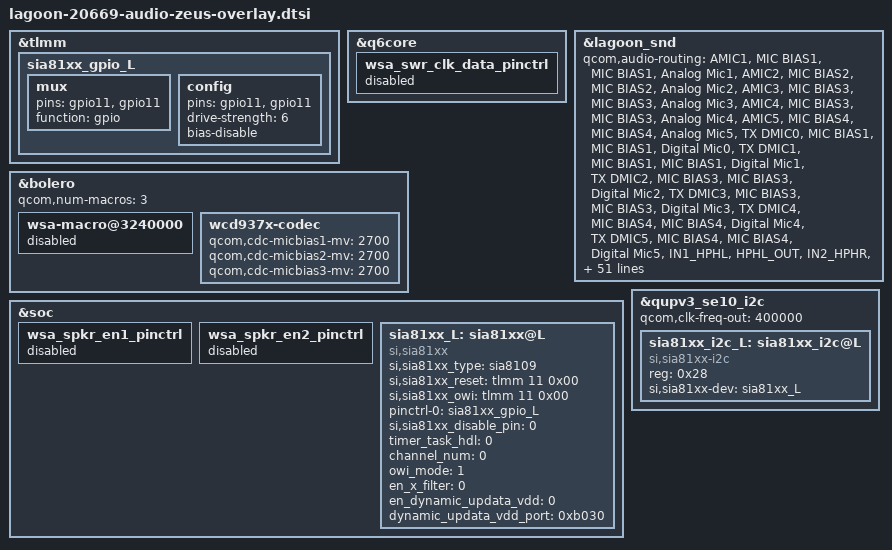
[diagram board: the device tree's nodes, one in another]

&tlmm {
	/* #ifdef OPLUS_ARCH_EXTENDS */
	sia81xx_gpio_L: sia81xx_gpio_L {
		mux {
			pins = "gpio11", "gpio11";
			function = "gpio";
		};

		config {
			pins = "gpio11", "gpio11";
			drive-strength = <6>;
			bias-disable;
		};
	};
	//#endif /* OPLUS_ARCH_EXTENDS */
};

&q6core {
        wsa_swr_clk_data_pinctrl {
                status = "disabled";
        };
};

&lagoon_snd {
	qcom,audio-routing =
		"AMIC1", "MIC BIAS1",
		"MIC BIAS1", "Analog Mic1",
		"AMIC2", "MIC BIAS2",
		"MIC BIAS2", "Analog Mic2",
		"AMIC3", "MIC BIAS3",
		"MIC BIAS3", "Analog Mic3",
		"AMIC4", "MIC BIAS3",
		"MIC BIAS3", "Analog Mic4",
		"AMIC5", "MIC BIAS4",
		"MIC BIAS4", "Analog Mic5",
		"TX DMIC0", "MIC BIAS1",
		"MIC BIAS1", "Digital Mic0",
		"TX DMIC1", "MIC BIAS1",
		"MIC BIAS1", "Digital Mic1",
		"TX DMIC2", "MIC BIAS3",
		"MIC BIAS3", "Digital Mic2",
		"TX DMIC3", "MIC BIAS3",
		"MIC BIAS3", "Digital Mic3",
		"TX DMIC4", "MIC BIAS4",
		"MIC BIAS4", "Digital Mic4",
		"TX DMIC5", "MIC BIAS4",
		"MIC BIAS4", "Digital Mic5",
		"IN1_HPHL", "HPHL_OUT",
		"IN2_HPHR", "HPHR_OUT",
		"IN3_AUX", "AUX_OUT",
		"TX SWR_ADC0", "ADC1_OUTPUT",
		//#ifdef OPLUS_ARCH_EXTENDS
		"TX SWR_ADC2", "ADC2_OUTPUT",
		//#else
		//"TX SWR_ADC1", "ADC2_OUTPUT",
		//"TX SWR_ADC2", "ADC3_OUTPUT",
		//#endif /* OPLUS_ARCH_EXTENDS */
		"TX SWR_ADC3", "ADC4_OUTPUT",
		"TX SWR_DMIC0", "DMIC1_OUTPUT",
		"TX SWR_DMIC1", "DMIC2_OUTPUT",
		"TX SWR_DMIC2", "DMIC3_OUTPUT",
		"TX SWR_DMIC3", "DMIC4_OUTPUT",
		"TX SWR_DMIC4", "DMIC5_OUTPUT",
		"TX SWR_DMIC5", "DMIC6_OUTPUT",
		"TX SWR_DMIC6", "DMIC7_OUTPUT",
		"TX SWR_DMIC7", "DMIC8_OUTPUT",
		"WSA SRC0_INP", "SRC0",
		"WSA_TX DEC0_INP", "TX DEC0 MUX",
		"WSA_TX DEC1_INP", "TX DEC1 MUX",
		"RX_TX DEC0_INP", "TX DEC0 MUX",
		"RX_TX DEC1_INP", "TX DEC1 MUX",
		"RX_TX DEC2_INP", "TX DEC2 MUX",
		"RX_TX DEC3_INP", "TX DEC3 MUX",
		"SpkrLeft IN", "WSA_SPK1 OUT",
		"SpkrRight IN", "WSA_SPK2 OUT",
		"VA_AIF1 CAP", "VA_SWR_CLK",
		"VA_AIF2 CAP", "VA_SWR_CLK",
		"VA_AIF3 CAP", "VA_SWR_CLK",
		"VA MIC BIAS1", "Digital Mic0",
		"VA MIC BIAS1", "Digital Mic1",
		"VA MIC BIAS3", "Digital Mic2",
		"VA MIC BIAS3", "Digital Mic3",
		"VA MIC BIAS4", "Digital Mic4",
		"VA MIC BIAS4", "Digital Mic5",
		"VA DMIC0", "VA MIC BIAS1",
		"VA DMIC1", "VA MIC BIAS1",
		"VA DMIC2", "VA MIC BIAS3",
		"VA DMIC3", "VA MIC BIAS3",
		"VA DMIC4", "VA MIC BIAS4",
		"VA DMIC5", "VA MIC BIAS4",
		"VA SWR_ADC0", "VA_SWR_CLK",
		"VA SWR_ADC1", "VA_SWR_CLK",
		"VA SWR_ADC2", "VA_SWR_CLK",
		"VA SWR_ADC3", "VA_SWR_CLK",
		"VA SWR_MIC0", "VA_SWR_CLK",
		"VA SWR_MIC1", "VA_SWR_CLK",
		"VA SWR_MIC2", "VA_SWR_CLK",
		"VA SWR_MIC3", "VA_SWR_CLK",
		"VA SWR_MIC4", "VA_SWR_CLK",
		"VA SWR_MIC5", "VA_SWR_CLK",
		"VA SWR_MIC6", "VA_SWR_CLK",
		"VA SWR_MIC7", "VA_SWR_CLK",
		"VA SWR_ADC0", "ADC1_OUTPUT",
		//#ifdef OPLUS_ARCH_EXTENDS
		"VA SWR_ADC2", "ADC2_OUTPUT",
		//#else /* OPLUS_ARCH_EXTENDS */
		//"VA SWR_ADC1", "ADC2_OUTPUT",
		//"VA SWR_ADC2", "ADC3_OUTPUT",
		//#endif /* OPLUS_ARCH_EXTENDS */
		"VA SWR_ADC3", "ADC4_OUTPUT",
		"VA SWR_MIC0", "DMIC1_OUTPUT",
		"VA SWR_MIC1", "DMIC2_OUTPUT",
		"VA SWR_MIC2", "DMIC3_OUTPUT",
		"VA SWR_MIC3", "DMIC4_OUTPUT",
		"VA SWR_MIC4", "DMIC5_OUTPUT",
		"VA SWR_MIC5", "DMIC6_OUTPUT",
		"VA SWR_MIC6", "DMIC7_OUTPUT",
		"VA SWR_MIC7", "DMIC8_OUTPUT";

        qcom,wsa-max-devs = <0>;
        qcom,codec-max-aux-devs = <1>;
	
        qcom,msm-mbhc-hs-mic-max-threshold-mv = <2600>;
        qcom,msm-mbhc-hs-mic-min-threshold-mv = <75>;

        oplus,mbhc-check-cross-conn = <0>;

        qcom,codec-aux-devs = <&wcd937x_codec>;
	//#ifdef OPLUS_ARCH_EXTENDS
        si,sia81xx-max-num = <1>;
        si,sia81xx-aux-devs = <&sia81xx_L>;
        si,sia81xx-aux-devs-prefix = "SpkrMonoL";
	//#endif /* OPLUS_ARCH_EXTENDS */

	//#ifdef OPLUS_ARCH_EXTENDS
	/* Huilong.Wen@LQ MULTIMEDIA.AUDIODRIVER.HeadsetDet, 2021/2/4, workaround to fix headset recording pop noise*/
	oplus,mbhc-headset-bias-alwayon = <1>;
	//#endif /* OPLUS_ARCH_EXTENDS */
 	oplus,speaker-vendor = "sia81xx";
};

&bolero {
        qcom,num-macros = <3>;

        wsa-macro@3240000 {
                status = "disabled";
        };

        wcd937x-codec {
                qcom,cdc-micbias1-mv = <2700>;
                qcom,cdc-micbias2-mv = <2700>;
                qcom,cdc-micbias3-mv = <2700>;
        };
};

&soc {

        wsa_spkr_en1_pinctrl {
                status = "disabled";
        };
        wsa_spkr_en2_pinctrl {
                status = "disabled";
        };

	//#ifdef OPLUS_ARCH_EXTENDS
	sia81xx_L: sia81xx@L {
			compatible = "si,sia81xx";
			si,sia81xx_type = "sia8109";
			si,sia81xx_reset = <&tlmm 11 0x00>;
			si,sia81xx_owi = <&tlmm 11 0x00>;
			pinctrl-names = "sia81xx_gpio";
			pinctrl-0 = <&sia81xx_gpio_L>;

			si,sia81xx_disable_pin = <0>;

			/* the same value share a same task
			 * valid value range : 0 ~ 7 */
			timer_task_hdl = <0>;

			channel_num = <0>;
			owi_mode = <1>;
			en_x_filter = <0>;
			en_dynamic_updata_vdd = <0>;
			dynamic_updata_vdd_port = <0xb030>;
	};
	//#endif /* OPLUS_ARCH_EXTENDS */
};

&qupv3_se10_i2c {
	status = "ok";
	qcom,clk-freq-out = <400000>;
	sia81xx_i2c_L: sia81xx_i2c@L {
		compatible = "si,sia81xx-i2c";
		reg = <0x28>;
		si,sia81xx-dev = <&sia81xx_L>;
	};
};
